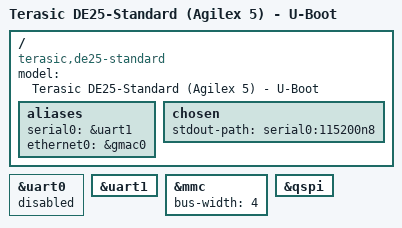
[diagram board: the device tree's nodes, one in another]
// SPDX-License-Identifier: GPL-2.0
/*
 * U-Boot device tree for the DE25-Standard.  Kept intentionally thin - the
 * SD-PHY tuning / memory / boot order come from socfpga_agilex5_socdk-u-boot.dtsi
 * (pulled in by socfpga_agilex5_de25-u-boot.dtsi); this file only picks the
 * console UART.  The build script installs it as
 * u-boot-socfpga/arch/arm/dts/socfpga_agilex5_de25.dts.
 */
#include "socfpga_agilex5.dtsi"

/ {
	model = "Terasic DE25-Standard (Agilex 5) - U-Boot";
	compatible = "terasic,de25-standard", "intel,socfpga-agilex5";

	aliases {
		serial0 = &uart1;
		ethernet0 = &gmac0;
	};

	chosen {
		stdout-path = "serial0:115200n8";
	};
};

&uart0 {
	status = "disabled";
};

&uart1 {
	status = "okay";
};

&mmc {
	status = "okay";
	bus-width = <4>;
};

&qspi {
	status = "okay";
};
